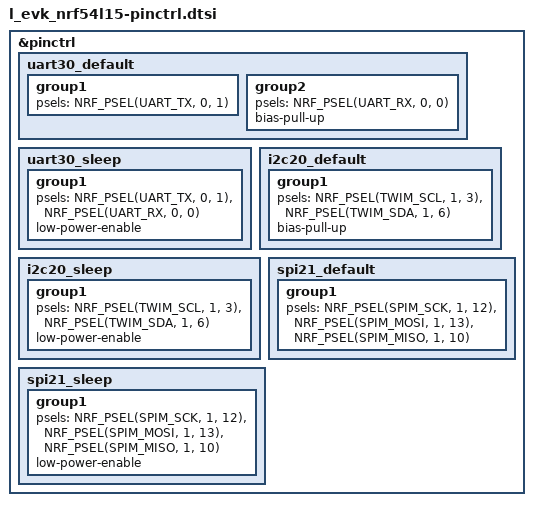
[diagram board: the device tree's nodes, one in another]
/* SPDX-License-Identifier: Apache-2.0 */

&pinctrl {
	uart30_default: uart30_default {
		group1 {
			psels = <NRF_PSEL(UART_TX, 0, 1)>;
		};

		group2 {
			psels = <NRF_PSEL(UART_RX, 0, 0)>;
			bias-pull-up;
		};
	};

	uart30_sleep: uart30_sleep {
		group1 {
			psels = <NRF_PSEL(UART_TX, 0, 1)>,
				<NRF_PSEL(UART_RX, 0, 0)>;
			low-power-enable;
		};
	};

	i2c20_default: i2c20_default {
		group1 {
			psels = <NRF_PSEL(TWIM_SCL, 1, 3)>,
				<NRF_PSEL(TWIM_SDA, 1, 6)>;
			bias-pull-up;
		};
	};

	i2c20_sleep: i2c20_sleep {
		group1 {
			psels = <NRF_PSEL(TWIM_SCL, 1, 3)>,
				<NRF_PSEL(TWIM_SDA, 1, 6)>;
			low-power-enable;
		};
	};

	spi21_default: spi21_default {
		group1 {
			psels = <NRF_PSEL(SPIM_SCK, 1, 12)>,
				<NRF_PSEL(SPIM_MOSI, 1, 13)>,
				<NRF_PSEL(SPIM_MISO, 1, 10)>;
		};
	};

	spi21_sleep: spi21_sleep {
		group1 {
			psels = <NRF_PSEL(SPIM_SCK, 1, 12)>,
				<NRF_PSEL(SPIM_MOSI, 1, 13)>,
				<NRF_PSEL(SPIM_MISO, 1, 10)>;
			low-power-enable;
		};
	};
};
